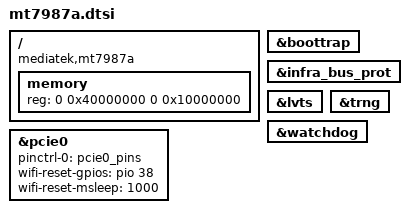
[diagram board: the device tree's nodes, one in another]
// SPDX-License-Identifier: (GPL-2.0 OR MIT)
/*
 * Copyright (C) 2023 MediaTek Inc.
 * Author: Sam.Shih <sam.shih@mediatek.com>
 */

/dts-v1/;
#include <dt-bindings/leds/common.h>
#include "mt7987.dtsi"
#include "mt7987-pinctrl.dtsi"
#include "mt7987-netsys.dtsi"

/ {
	compatible = "mediatek,mt7987a", "mediatek,mt7987";

	memory {
		reg = <0 0x40000000 0 0x10000000>;
	};
};

&boottrap {
	status = "okay";
};

&infra_bus_prot {
	status = "okay";
};

&lvts {
	status = "okay";
};

&trng {
	status = "okay";
};

&watchdog {
	status = "okay";
};


&pcie0 {
	pinctrl-names = "default";
	pinctrl-0 = <&pcie0_pins>;
	wifi-reset-gpios = <&pio 38 GPIO_ACTIVE_HIGH>;
        wifi-reset-msleep = <1000>;
	status = "okay";
};
